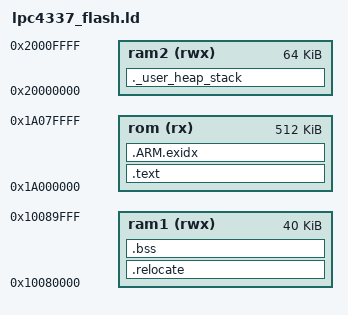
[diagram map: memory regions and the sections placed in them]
OUTPUT_FORMAT("elf32-littlearm", "elf32-littlearm", "elf32-littlearm")
OUTPUT_ARCH(arm)
SEARCH_DIR(.)

GROUP (
    libgcc.a
    libc.a
    libm.a
)

/* Highest address of the user mode stack */
_estack = 0x1008A000;    /* end of RAM */

/* Generate a link error if heap and stack don't fit into RAM */
_Min_Heap_Size = 63K;   /* required amount of heap  */
_Min_Stack_Size = 1K;    /* required amount of stack */

/* Memory Spaces Definitions */
MEMORY
{
  rom (rx)   : ORIGIN = 0x1A000000, LENGTH = 512K
  ram1 (rwx) : ORIGIN = 0x10080000, LENGTH = 40K
  ram2 (rwx) : ORIGIN = 0x20000000, LENGTH = 64K
}

/* The stack size used by the application. NOTE: you need to adjust according to your application. */
STACK_SIZE = DEFINED(STACK_SIZE) ? STACK_SIZE : 0x2000;

SECTIONS
{
    .text :
    {
        . = ALIGN(4);
        _sfixed = .;
        KEEP(*(.vectors .vectors.*))
        *(.text .text.* .gnu.linkonce.t.*)
        *(.glue_7t) *(.glue_7)
        *(.rodata .rodata* .gnu.linkonce.r.*)
        *(.ARM.extab* .gnu.linkonce.armextab.*)

        /* Support C constructors, and C destructors in both user code
           and the C library. This also provides support for C++ code. */
        . = ALIGN(4);
        KEEP(*(.init))
        . = ALIGN(4);
        __preinit_array_start = .;
        KEEP (*(.preinit_array))
        __preinit_array_end = .;

        . = ALIGN(4);
        __init_array_start = .;
        KEEP (*(SORT(.init_array.*)))
        KEEP (*(.init_array))
        __init_array_end = .;

        . = ALIGN(0x4);
        KEEP (*crtbegin.o(.ctors))
        KEEP (*(EXCLUDE_FILE (*crtend.o) .ctors))
        KEEP (*(SORT(.ctors.*)))
        KEEP (*crtend.o(.ctors))

        . = ALIGN(4);
        KEEP(*(.fini))

        . = ALIGN(4);
        __fini_array_start = .;
        KEEP (*(.fini_array))
        KEEP (*(SORT(.fini_array.*)))
        __fini_array_end = .;

        KEEP (*crtbegin.o(.dtors))
        KEEP (*(EXCLUDE_FILE (*crtend.o) .dtors))
        KEEP (*(SORT(.dtors.*)))
        KEEP (*crtend.o(.dtors))

        . = ALIGN(4);
        _efixed = .;            /* End of text section */
    } > rom

    /* .ARM.exidx is sorted, so has to go in its own output section.  */
    PROVIDE_HIDDEN (__exidx_start = .);
    .ARM.exidx :
    {
      *(.ARM.exidx* .gnu.linkonce.armexidx.*)
    } > rom
    PROVIDE_HIDDEN (__exidx_end = .);

    . = ALIGN(4);
    _etext = .;

    .relocate : AT (_etext)
    {
        . = ALIGN(4);
        _srelocate = .;
        *(.ramfunc .ramfunc.*);
        *(.data .data.*);
        . = ALIGN(4);
        _erelocate = .;
    } > ram1

    /* .bss section which is used for uninitialized data */
    .bss (NOLOAD) :
    {
        . = ALIGN(4);
        _sbss = . ;
        _szero = .;
        *(.bss .bss.*)
        *(COMMON)
        . = ALIGN(4);
        _ebss = . ;
        _ezero = .;
    } > ram1

    /* User_heap_stack section, used to check that there is enough RAM left */
    ._user_heap_stack :
   {
        . = ALIGN(4);
        PROVIDE ( end = . );
        PROVIDE ( _end = . );
        . = . + _Min_Heap_Size;
        PROVIDE ( _max_heap = . );
        . = . + _Min_Stack_Size;
        . = ALIGN(4);
    } > ram2
}
